VERSION ""

NS_ :

BS_:

BU_:

BO_ 3221225472 VECTOR__INDEPENDENT_SIG_MSG: 0 Vector__XXX
 SG_ Low_FlowRate : 0|8@1+ (1,0) [0|0] "" Vector__XXX
 SG_ INV_RadTemp : 16|8@1+ (1,0) [0|0] "" Vector__XXX
 SG_ INV_FlowRate : 0|8@1+ (1,0) [0|0] "" Vector__XXX
 SG_ RL_BellCrank : 8|8@1+ (1,0) [0|0] "" Vector__XXX

BO_ 912 HEARTBEAT: 8 Vector__XXX
 SG_ State : 0|8@1+ (1,0) [0|0] "" Vector__XXX
 SG_ Counter : 8|8@1+ (1,0) [0|0] "" Vector__XXX

BO_ 913 ERROR: 8 Vector__XXX
 SG_ A : 0|8@1+ (1,0) [0|0] "" Vector__XXX

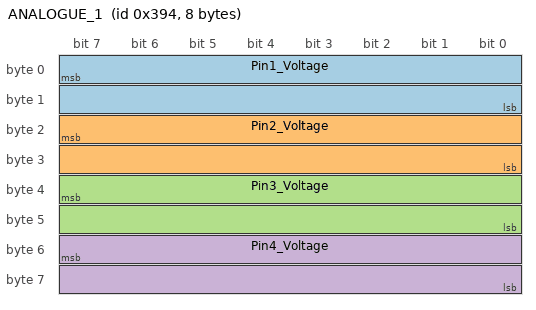
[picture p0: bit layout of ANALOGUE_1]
BO_ 916 ANALOGUE_1: 8 Vector__XXX
 SG_ Pin1_Voltage : 7|16@0+ (0.001,0) [0|0] "V" Vector__XXX
 SG_ Pin2_Voltage : 23|16@0+ (0.001,0) [0|0] "V" Vector__XXX
 SG_ Pin3_Voltage : 39|16@0+ (0.001,0) [0|0] "V" Vector__XXX
 SG_ Pin4_Voltage : 55|16@0+ (0.001,0) [0|0] "V" Vector__XXX

BO_ 917 ANALOGUE_2: 8 Vector__XXX
 SG_ INV_RAD_INLET_TEMP : 7|16@0+ (0.01,0) [0|0] "C" Vector__XXX
 SG_ INV_RAD_OUTLET_TEMP : 23|16@0+ (0.01,0) [0|0] "C" Vector__XXX
